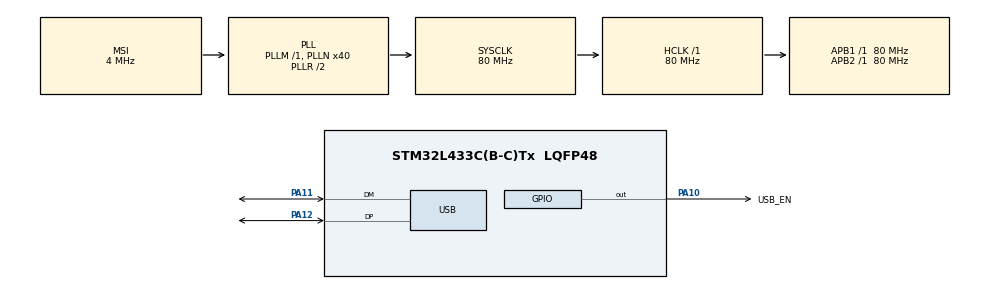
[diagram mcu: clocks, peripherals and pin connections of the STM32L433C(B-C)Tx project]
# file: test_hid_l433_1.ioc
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Mcu.Family=STM32L4
RCC.MSI_VALUE=4000000
PA14\ (JTCK-SWCLK).Mode=Serial_Wire
USB_DEVICE.CLASS_NAME_FS=CUSTOM_HID
RCC.CortexFreq_Value=80000000
NVIC.USB_IRQn=true\:0\:0\:false\:false\:true\:false\:true
USB_DEVICE.VirtualModeFS=Custom_Hid_FS
VP_USB_DEVICE_VS_USB_DEVICE_CUSTOM_HID_FS.Mode=CUSTOM_HID_FS
PA11.Mode=Device
VP_SYS_VS_tim16.Mode=TIM16
RCC.SYSCLKSource=RCC_SYSCLKSOURCE_PLLCLK
ProjectManager.StackSize=0x400
PA14\ (JTCK-SWCLK).Signal=SYS_JTCK-SWCLK
PA12.Signal=USB_DP
ProjectManager.TargetToolchain=STM32CubeIDE
PA10.PinState=GPIO_PIN_SET
RCC.HCLKFreq_Value=80000000
RCC.APB2TimFreq_Value=80000000
RCC.USBFreq_Value=48000000
RCC.LSE_VALUE=32768
RCC.AHBFreq_Value=80000000
RCC.HSE_VALUE=8000000
board=custom
RCC.VCOOutputFreq_Value=160000000
RCC.APB2Freq_Value=80000000
RCC.ADCFreq_Value=48000000
PA10.GPIO_Label=USB_EN
Mcu.Name=STM32L433C(B-C)Tx
PA13\ (JTMS-SWDIO).Mode=Serial_Wire
RCC.SYSCLKFreq_VALUE=80000000
Mcu.Package=LQFP48
NVIC.TimeBase=TIM1_UP_TIM16_IRQn
PA12.Mode=Device
PA11.Signal=USB_DM
NVIC.TimeBaseIP=TIM16
PA10.Signal=GPIO_Output
ProjectManager.HeapSize=0x400
RCC.HSI_VALUE=16000000
NVIC.TIM1_UP_TIM16_IRQn=true\:0\:0\:false\:false\:true\:false\:true
NVIC.PriorityGroup=NVIC_PRIORITYGROUP_4
RCC.PLLN=40
RCC.APB1TimFreq_Value=80000000
PA13\ (JTMS-SWDIO).Signal=SYS_JTMS-SWDIO
RCC.APB1Freq_Value=80000000
USB_DEVICE.VirtualMode=CustomHid
RCC.HSI48_VALUE=48000000
RCC.PLLSAI1N=24

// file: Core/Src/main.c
/* USER CODE BEGIN Header */
/**
 ******************************************************************************
 * @file           : main.c
 * @brief          : Main program body
 ******************************************************************************
 * @attention
 *
 * <h2><center>&copy; Copyright (c) 2021 STMicroelectronics.
 * All rights reserved.</center></h2>
 *
 * This software component is licensed by ST under Ultimate Liberty license
 * SLA0044, the "License"; You may not use this file except in compliance with
 * the License. You may obtain a copy of the License at:
 *                             www.st.com/SLA0044
 *
 ******************************************************************************
 */
/* USER CODE END Header */
#include "main.h"
#include "usb_device.h"
#include "gpio.h"

/* USER CODE BEGIN Includes */
#include <stdbool.h>
#include "usbd_custom_hid_if.h"
/* USER CODE END Includes */

/* USER CODE BEGIN PV */
extern uint8_t hid_in_report[64];
extern uint8_t hid_out_report[64];
extern bool is_hid_out_empty;
/* USER CODE END PV */

void SystemClock_Config(void);

int main(void)
{
  /* USER CODE BEGIN 1 */
	uint8_t i;

  /* USER CODE END 1 */

  /* MCU Configuration--------------------------------------------------------*/

  /* Reset of all peripherals, Initializes the Flash interface and the Systick. */
  HAL_Init();

  /* Configure the system clock */
  SystemClock_Config();

  /* Initialize all configured peripherals */
  MX_GPIO_Init();
  MX_USB_DEVICE_Init();
  /* USER CODE BEGIN 2 */
	for (i = 0; i < 64; i++)
	{
		hid_in_report[i] = 0;
		hid_out_report[i] = 0;
	}
	//MX_USB_DEVICE_Init();

  /* USER CODE END 2 */

  /* Infinite loop */
	while (1)
	{

    /* USER CODE BEGIN 3 */
		//HAL_Delay(1000);
		//USBD_CUSTOM_HID_SendReport_FS(hid_in_test, 64);
		if (is_hid_out_empty == false)
		{
			memcpy(hid_in_report, hid_out_report, 64); // copy from out => in
			for (int i = 0; i < 64; i++)
			{
				hid_in_report[i] = hid_in_report[i];
			}
			USBD_CUSTOM_HID_SendReport_FS(hid_in_report, 64);
			is_hid_out_empty = true;
		}
		HAL_Delay(1);
	}
  /* USER CODE END 3 */
}

void SystemClock_Config(void)
{
  RCC_OscInitTypeDef RCC_OscInitStruct = {0};
  RCC_ClkInitTypeDef RCC_ClkInitStruct = {0};
  RCC_PeriphCLKInitTypeDef PeriphClkInit = {0};

  /** Initializes the RCC Oscillators according to the specified parameters
  * in the RCC_OscInitTypeDef structure.
  */
  RCC_OscInitStruct.OscillatorType = RCC_OSCILLATORTYPE_MSI;
  RCC_OscInitStruct.MSIState = RCC_MSI_ON;
  RCC_OscInitStruct.MSICalibrationValue = 0;
  RCC_OscInitStruct.MSIClockRange = RCC_MSIRANGE_6;
  RCC_OscInitStruct.PLL.PLLState = RCC_PLL_ON;
  RCC_OscInitStruct.PLL.PLLSource = RCC_PLLSOURCE_MSI;
  RCC_OscInitStruct.PLL.PLLM = 1;
  RCC_OscInitStruct.PLL.PLLN = 40;
  RCC_OscInitStruct.PLL.PLLP = RCC_PLLP_DIV7;
  RCC_OscInitStruct.PLL.PLLQ = RCC_PLLQ_DIV2;
  RCC_OscInitStruct.PLL.PLLR = RCC_PLLR_DIV2;
  if (HAL_RCC_OscConfig(&RCC_OscInitStruct) != HAL_OK)
  {
    Error_Handler();
  }
  /** Initializes the CPU, AHB and APB buses clocks
  */
  RCC_ClkInitStruct.ClockType = RCC_CLOCKTYPE_HCLK|RCC_CLOCKTYPE_SYSCLK
                              |RCC_CLOCKTYPE_PCLK1|RCC_CLOCKTYPE_PCLK2;
  RCC_ClkInitStruct.SYSCLKSource = RCC_SYSCLKSOURCE_PLLCLK;
  RCC_ClkInitStruct.AHBCLKDivider = RCC_SYSCLK_DIV1;
  RCC_ClkInitStruct.APB1CLKDivider = RCC_HCLK_DIV1;
  RCC_ClkInitStruct.APB2CLKDivider = RCC_HCLK_DIV1;

  if (HAL_RCC_ClockConfig(&RCC_ClkInitStruct, FLASH_LATENCY_4) != HAL_OK)
  {
    Error_Handler();
  }
  PeriphClkInit.PeriphClockSelection = RCC_PERIPHCLK_USB;
  PeriphClkInit.UsbClockSelection = RCC_USBCLKSOURCE_PLLSAI1;
  PeriphClkInit.PLLSAI1.PLLSAI1Source = RCC_PLLSOURCE_MSI;
  PeriphClkInit.PLLSAI1.PLLSAI1M = 1;
  PeriphClkInit.PLLSAI1.PLLSAI1N = 24;
  PeriphClkInit.PLLSAI1.PLLSAI1P = RCC_PLLP_DIV7;
  PeriphClkInit.PLLSAI1.PLLSAI1Q = RCC_PLLQ_DIV2;
  PeriphClkInit.PLLSAI1.PLLSAI1R = RCC_PLLR_DIV2;
  PeriphClkInit.PLLSAI1.PLLSAI1ClockOut = RCC_PLLSAI1_48M2CLK;
  if (HAL_RCCEx_PeriphCLKConfig(&PeriphClkInit) != HAL_OK)
  {
    Error_Handler();
  }
  /** Configure the main internal regulator output voltage
  */
  if (HAL_PWREx_ControlVoltageScaling(PWR_REGULATOR_VOLTAGE_SCALE1) != HAL_OK)
  {
    Error_Handler();
  }
}

 /**
  * @brief  Period elapsed callback in non blocking mode
  * @note   This function is called  when TIM16 interrupt took place, inside
  * HAL_TIM_IRQHandler(). It makes a direct call to HAL_IncTick() to increment
  * a global variable "uwTick" used as application time base.
  * @param  htim : TIM handle
  * @retval None
  */
void HAL_TIM_PeriodElapsedCallback(TIM_HandleTypeDef *htim)
{
  if (htim->Instance == TIM16) {
    HAL_IncTick();
  }
}

void Error_Handler(void)
{
	__disable_irq();
	while (1)
	{
	}
}

/************************ (C) COPYRIGHT STMicroelectronics *****END OF FILE****/
